# tpu_reva_me10 register map
Registers are access not given, no defined reset value unless marked. A register's access mark holds for its fields unless they carry their own. Offsets are from the block's base; lines under a group give offsets from that group; [hi:lo] are bit positions; {n}, {i} and the like mark numbered series; 'fields as' and 'values as' point back to an identical list; <NAME> marks a mode.

## Memory map
0x40001000 TPU size 0x1000 — The Trust Protection Unit used to assist the computationally intensive operations of several common cryptographic algorithms.

## Interrupts
27 Crypto_Engine (TPU) — Crypto Engine interrupt.

## TPU — The Trust Protection Unit used to assist the computationally intensive operations of several common cryptographic algorithms.
Base 0x40001000
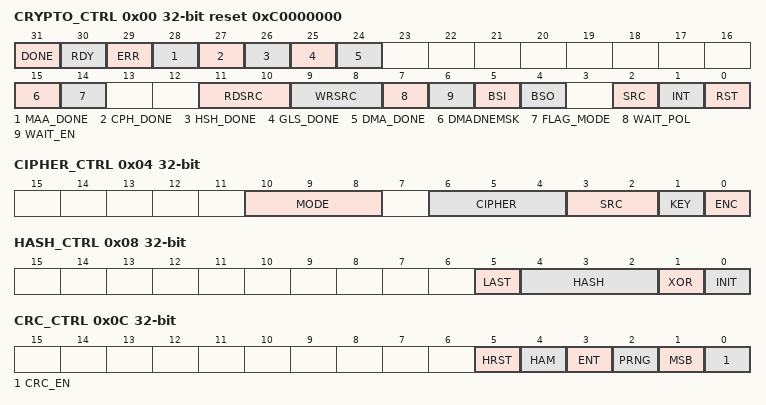
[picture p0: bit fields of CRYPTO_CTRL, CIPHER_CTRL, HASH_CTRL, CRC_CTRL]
0x00 CRYPTO_CTRL reset 0xC0000000 — Crypto Control Register.
  [31] DONE ro — Done. One or more cryptographic calculations complete (logical OR of done flags).
    0=notDone; 1=done
  [30] RDY ro — Ready. Crypto block ready for more data.
    0=busy; 1=ready
  [29] ERR ro — AHB Bus Error. This bit is set when the DMA encounters a bus error during a read or write operation. Once this bit is set, the DMA will stop. This bit can only be cleared by resetting the crypto block.
    0=noError; 1=error
  [28] MAA_DONE — MAA Done. MAA operation is complete. This bit must be cleared before starting a new MAA operation. This bit is read only while the MAA is in progress. This bit is negate of MAA_CTRL.STC.
    0=notDone; 1=done
  [27] CPH_DONE — Cipher Done. Either AES or DES encryption/decryption operation is complete. This bit must be cleared before starting a cipher operation.
    0=notDone; 1=done
  [26] HSH_DONE — Hash Done. SHA operation is complete. This bit must be cleared before starting a HASH operation.
    0=notDone; 1=done
  [25] GLS_DONE — Galois Done. FIFO is full and CRC or Hamming Code Generator is enabled. This bit must be cleared before starting a CRC operation Note that DMA_DONE must be polled instead of this bit to determine the end of DMA operation during the utilization of Hamming Code Generator.
    0=notDone; 1=done
  [24] DMA_DONE — DMA Done. DMA write/read operation is complete. This bit must be cleared before starting a DMA operation.
    0=notDone; 1=done
  [15] DMADNEMSK — DMA Done Flag Mask. This bit masks the DMA_DONE flag from being used to generate the CRYPTO_CTRL.DONE flag, and this disables a DMA_DONE condition from generating and interrupt. The DMA_DONE flag itself is unaffected and still may be monitored. This allows more optimal interrupt-driven crypto operations using DMA.
    0=not_used (DMA_DONE not used in setting CRYPTO_CTRL.DONE bit.); 1=used (DMA_DONE used in setting CRYPTO_CTRL.DONE bit.)
  [14] FLAG_MODE — Done Flag Mode. This bit configures the access behavior of the individual CRYPTO_CTRL Done flags (CRYPTO_CTRL[27:24]). This bit is cleared only on reset to limit upkeep, i.e. once set, it will remain set until a reset occurs.
    0=unres_wr (Unrestricted write (0 or 1) of CRYPTO_CTRL[27:24] flags.); 1=res_wr (Access to CRYPTO_CTRL[27:24] are write 1 to clear/write 0 no effect.)
  [11:10] RDSRC — Read FIFO Source Select. This field selects the source of the read FIFO. Typically, it is set to use the DMA. To implement a memset() function, the read FIFO DMA should be disabled. To fill memory with random data or to hash random numbers, the read FIFO source should be set to the random number generator.
    0=dmaDisabled; 1=dmaOrApb; 2=rng
  [9:8] WRSRC — Write FIFO Source Select. This field determines where data written to the write FIFO comes from. When data is written to the write FIFO, it is always written out the DMA. To decrypt or encrypt data, the write FIFO source should be set to the cipher output. To implement memcpy() or memset() functions, or to fill memory with random data, the write FIFO source should be set to the read FIFO. When calculating a HASH or CMAC, the write FIFO should be disabled.
    0=none; 1=cipherOutput; 2=readFIFO
  [7] WAIT_POL — Wait Pin Polarity. When the wait pin is enabled, this bit selects its active state.
    0=Active Low; 1=Active High
  [6] WAIT_EN — Wait Pin Enable. This can be used to hold off the crypto DMA until an external memory is ready. This is useful for transferring pages from NAND flash which may take several microseconds to become ready.
    0=dis (Disable); 1=en (Enable)
  [5] BSI — Byte Swap Input. Note. No byte swap will occur if there is not a full word.
    0=dis (Disable); 1=en (Enable)
  [4] BSO — Byte Swap Output. Note. No byte swap will occur if there is not a full word.
    0=dis (Disable); 1=en (Enable)
  [2] SRC — Source Select. This bit selects the hash function and CRC generator input source.
    0=inputFIFO; 1=outputFIFO
  [1] INT — Interrupt Enable. Generates an interrupt when done or error set.
    0=dis (Disable); 1=en (Enable)
  [0] RST — Reset. This bit is used to reset the crypto accelerator. All crypto internal states and related registers are reset to their default reset values. Control register such as CRYPTO_CTRL, CIPHER_CTRL, HASH_CTRL, CRC_CTRL, MAA_CTRL (with the exception of the STC bit), HASH_MSG_SZ_[3:0] and MAA_MAWS will retain their values. This bit will automatically clear itself after one cycle.
    on write: 1=reset (Starts reset operation.) | on read: 0=reset_done (Reset complete.); 1=busy (Reset in progress.)
0x04 CIPHER_CTRL — Cipher Control Register.
  [10:8] MODE — Mode Select. Mode of operation for block cipher or memory operation. DES/TDES cannot be used in CFB, OFB or CTR modes.
    0=ECB (ECB Mode.); 1=CBC (CBC Mode.); 2=CFB (CFB (AES only).); 3=OFB (OFB (AES only).); 4=CTR (CTR (AES only).)
  [6:4] CIPHER — Cipher Operation Select. Symmetric Block Cipher algorithm selection or memory operation.
    0=dis (Disabled.); 1=aes128; 2=aes192; 3=aes256; 4=des; 5=tdea (Triple DES.)
  [3:2] SRC — Source of Random key.
    0=cipherKey (User cipher key (0x4000_1060).); 2=regFile (Key from battery-backed register file (0x4000_5000 to 0x4000_501F).); 3=qspiKey_regFile (Key from battery-backed register file (0x4000_5020 to 0x4000_502F).)
  [1] KEY — Load Key from crypto DMA. This bit is automatically cleared by hardware after the DMA has completed loading the key. When the DMA operation is done, it sets the appropriate crypto DMA Done flag.
    0=complete (No operation/complete.); 1=Start operation
  [0] ENC — Encrypt. Select encryption or decryption of input data.
    0=encrypt; 1=decrypt
0x08 HASH_CTRL — HASH Control Register.
  [5] LAST — Last Message Bit. This bit shall be set along with the HASH_MSG_SZ register prior to hashing the last 512 or 1024-bit block of the message data. It will allow automatic preprocessing of the last message padding, which includes the trailing bit 1, followed by the respective number of zero bits for the last block size and finally the message length represented in bytes. The bit will be automatically cleared at the same time the HASH DONE is set, designating the completion of the last message hash.
    0=noEffect; 1=lastMsgData (Last Message Data.)
  [4:2] HASH — Hash function selection.
    0=dis (Disabled.); 1=sha1; 2=sha224; 3=sha256; 4=sha384; 5=sha512
  [1] XOR — XOR data with IV from cipher block. Useful when calculating HMAC to XOR the input pad and output pad.
    0=dis (Disable.); 1=en (Enable.)
  [0] INIT — Initialize. Initializes hash registers with standard constants.
    0=nop (No operation/complete.); 1=Start operation
0x0C CRC_CTRL — CRC Control Register.
  [5] HRST wo — Hamming Reset. Reset Hamming code ECC generator for next block.
    on write: 1=reset (Starts reset operation.)
  [4] HAM — Hamming Code Enable. Enable hamming code calculation.
    0=dis (Disable.); 1=en (Enable.)
  [3] ENT — Entropy Enable. If the PRNG is enabled, this mixes the high frequency ring oscillator with the LFSR. If the PRNG is disabled, the raw entropy data is output at a rate of 1 bit per clock. This makes it possible to characterize the quality of the entropy source.
    0=dis (Disable.); 1=en (Enable.)
  [2] PRNG — Pseudo Random Number Generator Enable. If entropy is disabled, this outputs one byte of pseudo random data per clock cycle. If entropy is enabled, data is output at a rate of one bit per clock cycle.
    0=dis (Disable.); 1=en (Enable.)
  [1] MSB — MSB select. This bit selects the order of calculating CRC on data.
    0=lsbFirst; 1=msbFirst
  [0] CRC_EN — Cyclic Redundancy Check Enable. The CRC cannot be enabled if the PRNG is enabled.
    0=dis (Disable.); 1=en (Enable.)
0x10 DMA_SRC — Crypto DMA Source Address.
  [31:0] ADDR — DMA Source Address.
0x14 DMA_DEST — Crypto DMA Destination Address.
  [31:0] ADDR — DMA Destination Address.
0x18 DMA_CNT — Crypto DMA Byte Count.
  [31:0] COUNT — DMA Byte Address.
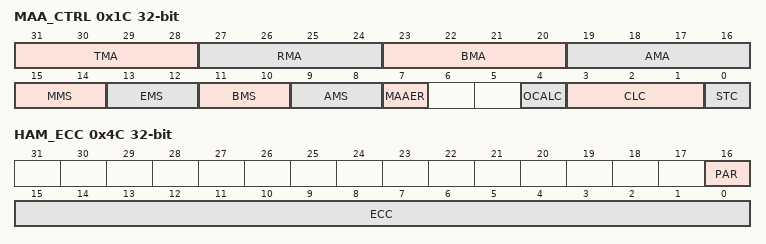
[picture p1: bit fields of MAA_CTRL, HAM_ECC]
0x1C MAA_CTRL — MAA Control Register.
  [31:28] TMA — Temporary Memory Assignment. These bits select the logical cryptographic RAM segment for the parameter 't'.
  [27:24] RMA — Result Memory Assignment. These bits select the logical cryptographic RAM segment for the parameter 'r'.
  [23:20] BMA — Multiplicand / Operand B Memory Assignment. These bits select the logical cryptographic RAM segment for the parameter 'b'.
  [19:16] AMA — Multiplier / Operand A Memory Assignment. These bits select the logical cryptographic RAM segment for the parameter 'a'.
  [15:14] MMS — Modulus Memory Select. These bits select the starting position of the parameter 'm' within the logical segment 5.
  [13:12] EMS — Exponent Memory Select. These bits select the starting position of the parameter 'e' within the logical segment specified by EMA.
  [11:10] BMS — Multiplicand B Memory Select. These bits select the starting position of the parameter 'b' within the logical segment specified by BMA.
  [9:8] AMS — Multiplier A Memory Select. These bits select the starting position of the parameter 'a' within the logical segment specified by AMA.
  [7] MAAER — MAA Error. The MAAER bit defaults to 0 and can only be set by hardware. Once set, it must be cleared by software otherwise no new operation can be initiated. Software writes 1 to this bit has no effect and MAAER will maintain its original state.
    0=noError; 1=error
  [4] OCALC — Optimized Calculation Control. For optimized calculation, unnecessary multiply operations after normalizing the exponent are skipped.
    0=none (No optimization.); 1=Optimize calculation
  [3:1] CLC — Calculation Configuration. These bits select desired calculation.
    0=exp (Exponentiation.); 1=sq (Square operation.); 2=Multiplication; 3=sq_mult (Square followed by a multiplication.); 4=add (Addition.); 5=sub (Subtraction.)
  [0] STC — Start Calculation. This bit functions as both the control and the status of the MAA. If the size value in the MAWS register is invalid, the STC bit will be cleared by hardware immediately. Otherwise, the STC bit is automatically cleared following the completion of each calculation or detecting an error. Clearing the STC bit resets the controller to its default state.
    0=nop (No operation/complete.); 1=Start operation
{0x20+4i} CRYPTO_DIN[{i}] (i=0..3) wo — Crypto Data Input. Data input can be written to this register instead of using the DMA. This register writes to the FIFO. This register occupies four successive words to allow the use of multi-store instructions. Words can be written to any location, they will be placed in the FIFO in the order they are written. The endian swap input control bit affects this register.
  [31:0] DATA — Crypto Data Input. Input can be written to this register instead of using DMA.
{0x30+4i} CRYPTO_DOUT[{i}] (i=0..3) ro — Crypto Data Output. Resulting data from cipher calculation. Data is placed in the lower words of these four registers depending on the algorithm. For block cipher modes, this register holds the result of most recent encryption or decryption operation. These registers are affected by the endian swap bits.
  [31:0] DATA — Crypto Data Output. Resulting data from cipher calculation. Data is placed in the lower words of these four registers depending on algorithm.
0x40 CRC_POLY reset 0xEDB88320 — CRC Polynomial. The polynomial to be used for Galois Field calculations (CRC or LFSR) should be written to this register. This register is affected by the MSB control bit.
  [31:0] POLY
0x44 CRC_VAL reset 0xFFFFFFFF — CRC Value. This is the state for the Galois Field. This register holds the result of a CRC calculation or the current state of the LFSR. This register is affected by the MSB control bit.
  [31:0] VAL — CRC Value. This is the state for the Galois Field. This register holds the result of a CRC calculation or the current state of LFSR. This register is affected by the MSB control bit.
0x48 CRC_PRNG ro — Pseudo Random Value. Output of the Galois Field shift register. This holds the resulting pseudo-random number if entropy is disabled or true random number if entropy is enabled.
  [31:0] PRNG — Pseudo Random Value. Output of the Galois Field Shift Register. This holds the resulting pseudo-random number if entropy is disabled or true random number if entropy is enabled.
0x4C HAM_ECC — Hamming ECC Register.
  [16] PAR — Parity. This is the parity of the entire array.
    0=even; 1=odd
  [15:0] ECC — Hamming ECC Value. These bits are the even parity of their corresponding bit groups.
{0x50+4i} CIPHER_INIT[{i}] (i=0..3) — Initial Vector. For block cipher operations that use CBC, CFB, OFB, or CNTR modes, this register holds the initial value. This register is updated with each encryption or decryption operation. This register is affected by the endian swap bits.
  [31:0] IVEC
{0x60+4i} CIPHER_KEY[{i}] (i=0..7) wo — Cipher Key. This register holds the key used for block cipher operations. The lower words are used for block ciphers that use shorter key lengths. This register is affected by the endian swap input control bits.
  [31:0] KEY — Cipher Key. This register holds the key used for block cipher operations. The lower words are used for block ciphers that use shorter kye lengths. This register is affected by the endian swap input control bits.
{0x80+4i} HASH_DIGEST[{i}] (i=0..15) — This register holds the calculated hash value. This register is affected by the endian swap bits.
  [31:0] HASH
{0xC0+4i} HASH_MSG_SZ[{i}] (i=0..3) — Message Size. This register holds the lowest 32-bit of message size in bytes.
  [31:0] MSGSZ
0xD0 MAA_MAWS — MAA Word Size. This register defines the number of bits for a modular operation. This register must be set to a valid value prior to the MAA operation start. Valid values are from 1 to 2048. Invalid values are ignored and will not initiate a MAA operation.
  [11:0] MSGSZ — MAA Word Size.
